# RL7005_IP_SVD register map
Vendor: Realtek
Registers are 32-bit, read-write, reset 0x0 unless marked. A register's access mark holds for its fields unless they carry their own. Offsets are from the block's base; [hi:lo] are bit positions; <NAME> marks a mode.

## PAGE5 (part 2 of 2)
Base 0x40000000
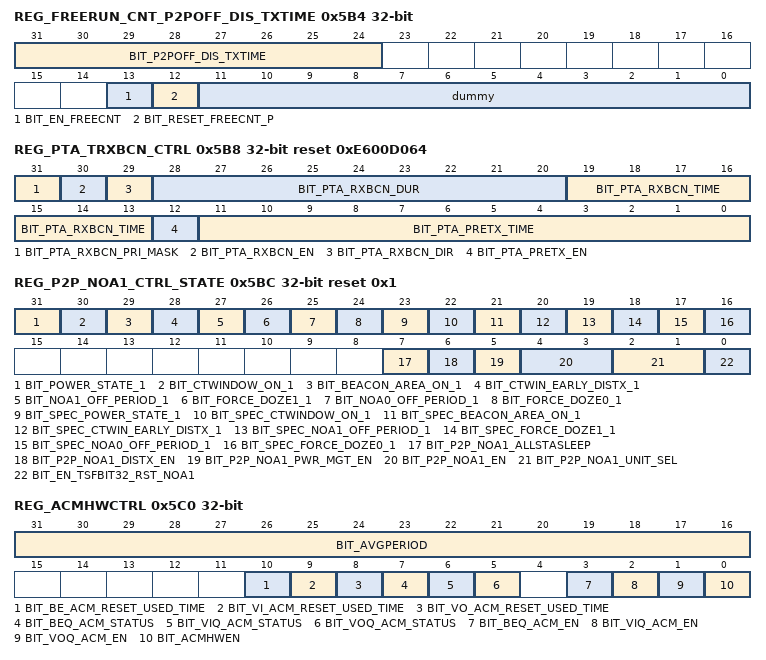
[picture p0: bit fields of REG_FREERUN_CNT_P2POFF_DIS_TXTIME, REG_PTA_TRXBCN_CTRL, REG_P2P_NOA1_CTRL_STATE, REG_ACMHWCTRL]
0x5B4 REG_FREERUN_CNT_P2POFF_DIS_TXTIME access per field
  [31:24] BIT_P2POFF_DIS_TXTIME rw — The time of the disable TX period after the P2P RF off interrupt occur. Unit: 64us.
  [13] BIT_EN_FREECNT rw — enable freerun tsft
  [12] BIT_RESET_FREECNT_P wo — reset pulse of freerun tsft
  [11:0] dummy rw
0x5B8 REG_PTA_TRXBCN_CTRL reset 0xE600D064
  [31] BIT_PTA_RXBCN_PRI_MASK
  [30] BIT_PTA_RXBCN_EN
  [29] BIT_PTA_RXBCN_DIR
  [28:20] BIT_PTA_RXBCN_DUR
  [19:13] BIT_PTA_RXBCN_TIME
  [12] BIT_PTA_PRETX_EN
  [11:0] BIT_PTA_PRETX_TIME — WIFI TX shall wait settle time when antenna is switched from BT to WIFI, if the BT use the same RFAFE as WIFI. Unit: 1us
0x5BC REG_P2P_NOA1_CTRL_STATE access per field reset 0x1
  [31] BIT_POWER_STATE_1 ro — 1: On, 0: Off. (It is including early time. )
  [30] BIT_CTWINDOW_ON_1 ro — Spec time and Beacon Early Time to TBTT Time. (It is including early time. )
  [29] BIT_BEACON_AREA_ON_1 ro — The time is from HOLD Time to BeaconTx or Timeout. (It is including early time. )
  [28] BIT_CTWIN_EARLY_DISTX_1 ro — ctwin_early_distx. (It is including early time. )
  [27] BIT_NOA1_OFF_PERIOD_1 ro — Spec time but exclude BCNDMATIM time for wake. (It is including early time. )
  [26] BIT_FORCE_DOZE1_1 ro — If NoA_Count == 1, this value is 1. else 0. (It is including early time. )
  [25] BIT_NOA0_OFF_PERIOD_1 ro — Spec time but exclude BCNDMATIM time for wake. (It is including early time. )
  [24] BIT_FORCE_DOZE0_1 ro — If NoA_Count == 1, this value is 1. else 0. (It is including early time. )
  [23] BIT_SPEC_POWER_STATE_1 ro — 1: On, 0: Off
  [22] BIT_SPEC_CTWINDOW_ON_1 ro — The time from TBTT <-> CTWEND (with BCNDMATIM early time)
  [21] BIT_SPEC_BEACON_AREA_ON_1 ro — The time is from TBTT to BeaconTx or Timeout
  [20] BIT_SPEC_CTWIN_EARLY_DISTX_1 ro — ctwin_early_distx
  [19] BIT_SPEC_NOA1_OFF_PERIOD_1 ro — Spec time
  [18] BIT_SPEC_FORCE_DOZE1_1 ro — If NoA_Count == 1, this value is 1. else 0.
  [17] BIT_SPEC_NOA0_OFF_PERIOD_1 ro — Spec time
  [16] BIT_SPEC_FORCE_DOZE0_1 ro — If NoA_Count == 1, this value is 1. else 0.
  [7] BIT_P2P_NOA1_ALLSTASLEEP rw — It indicates that the state from CTWindow End to BcnEarly 1: Sleep 0: Wake
  [6] BIT_P2P_NOA1_DISTX_EN rw — 1: Hw will disable TX in P2P_off period 0: Do Nothing
  [5] BIT_P2P_NOA1_PWR_MGT_EN rw — A main switch for P2P PowerSaving 1: Enable 0: Disable
  [4:3] BIT_P2P_NOA1_EN rw — The condition that noa_unit0, [1]-NOA1, [0]-NOA0 1: Enable 0: Disable
  [2:1] BIT_P2P_NOA1_UNIT_SEL rw — The selector for the source of noa unit0. 0 for port 0, 1 for port 1
  [0] BIT_EN_TSFBIT32_RST_NOA1 rw
0x5C0 REG_ACMHWCTRL access per field
  [31:16] BIT_AVGPERIOD rw — In unit of 32 us. It is the value Dot11EDCAAveragingPeriod in SPEC. HW will recalculate used_time every this period. Max is 2 sec
  [10] BIT_BE_ACM_RESET_USED_TIME wo — When HwEn is enabled, software set this bit to inform hardware to reset used_time to 0. Read this bit is always 0.
  [9] BIT_VI_ACM_RESET_USED_TIME wo — When HwEn is enabled, software set this bit to inform hardware to reset used_time to 0. Read this bit is always 0.
  [8] BIT_VO_ACM_RESET_USED_TIME wo — When HwEn is enabled, software set this bit to inform hardware to reset used_time to 0. Read this bit is always 0.
  [7] BIT_BEQ_ACM_STATUS ro — This bit indicates if the used_time >= admitted_time of AC BE when HW ACM. 0: BEQ ACM Not Exceed. 1: BEQ ACM Exceed. Default: 0h
  [6] BIT_VIQ_ACM_STATUS ro — This bit indicates if the used_time >= admitted_time of AC VI when HW ACM. 0: VIQ ACM Not Exceed. 1: VIQ ACM Exceed. Default: 0h
  [5] BIT_VOQ_ACM_STATUS ro — This bit indicates if the used_time >= admitted_time of AC VO when HW ACM. 0: VOQ ACM Not Exceed. 1: VOQ ACM Exceed. Default: 0h
  [3] BIT_BEQ_ACM_EN rw — Set this bit to enable ACM of BE queue. 1: Enable 0: Disable Default: 0h
  [2] BIT_VIQ_ACM_EN rw — Set this bit to enable ACM of VI queue. 1: Enable 0: Disable Default: 0h.
  [1] BIT_VOQ_ACM_EN rw — Set this bit to enable ACM of VO queue. 1: Enable 0: Disable Default: 0h.
  [0] BIT_ACMHWEN rw — Set this bit to enable hardware to take control of ACM. 1: Hardware Control 0: Software Control Default: 0h.
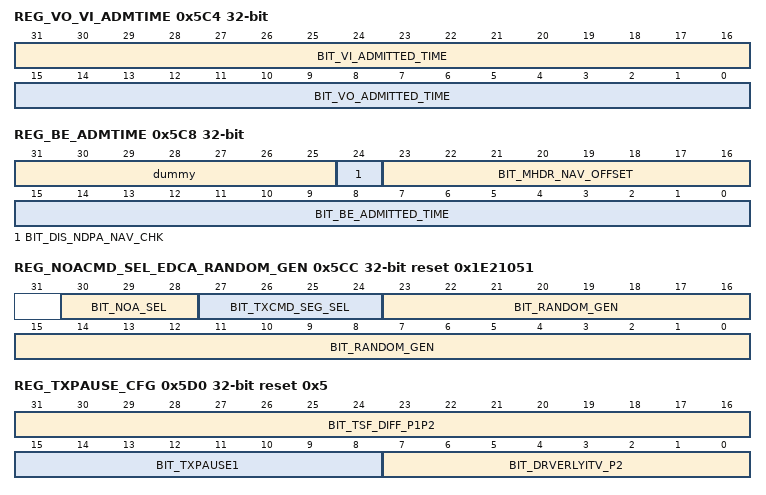
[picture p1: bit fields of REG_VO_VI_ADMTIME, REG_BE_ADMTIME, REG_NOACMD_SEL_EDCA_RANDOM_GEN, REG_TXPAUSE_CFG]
0x5C4 REG_VO_VI_ADMTIME
  [31:16] BIT_VI_ADMITTED_TIME — Admitted_time of VI queue. In unit of 32 microsecond. Calculated and set by driver.
  [15:0] BIT_VO_ADMITTED_TIME — Admitted_time of VO queue. In unit of 32 microsecond. Calculated and set by driver.
0x5C8 REG_BE_ADMTIME
  [31:25] dummy
  [24] BIT_DIS_NDPA_NAV_CHK — 1-->tx NDPA/NDP can cross TBTT,0-->tx NDPA/NDP can't cross TBTT
  [23:16] BIT_MHDR_NAV_OFFSET — NDPA NAV compensation value
  [15:0] BIT_BE_ADMITTED_TIME — Admitted_time of BE queue. In unit of 32 microsecond. Calculated and set by driver.
0x5CC REG_NOACMD_SEL_EDCA_RANDOM_GEN reset 0x1E21051
  [30:28] BIT_NOA_SEL — TX NoA parameter select (noa_unit0~2,parameter0~5) 0: NoA0 , 1:NoA1, 2:NoA2, 3:NoA3, 4:NoA4, default: NoA5 To control the register setting for which NOA. (register 0x05E0[103:0])
  [27:24] BIT_TXCMD_SEG_SEL — [HW Debug Info]To select which one TXCMD Segment. For example, 可以在0x5CF[3:0]填 0 or 6 讀取 0x5F8[7:0] : Tx Agg 0x5F9[7:0] : Tx Rate
  [23:0] BIT_RANDOM_GEN — Random number generator polynomial
0x5D0 REG_TXPAUSE_CFG access per field reset 0x5
  [31:16] BIT_TSF_DIFF_P1P2 ro — the difference of beacon count down value between port0 and port1, unit is TU
  [15:8] BIT_TXPAUSE1 rw — same as 0x522[7:0], allow FW/DR to control pause jointly
  [7:0] BIT_DRVERLYITV_P2 rw — Time to send interrupt to notify driver to change beacon content. Time unit is TU. It is used to wake up early at DriverEarlyTime. For port 2
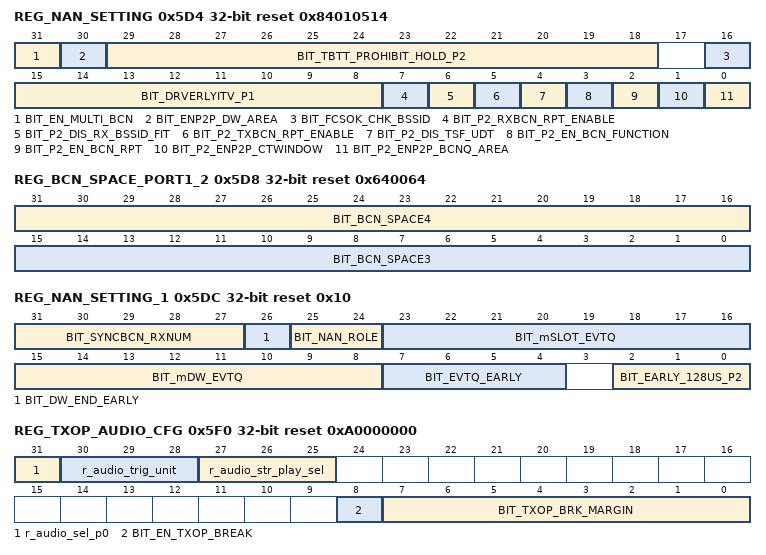
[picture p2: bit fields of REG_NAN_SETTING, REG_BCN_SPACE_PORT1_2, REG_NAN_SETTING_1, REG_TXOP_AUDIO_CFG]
0x5D4 REG_NAN_SETTING reset 0x84010514
  [31] BIT_EN_MULTI_BCN — enable multiple beacons of port0~port2
  [30] BIT_ENP2P_DW_AREA — DW condition for P2P,for port2
  [29:18] BIT_TBTT_PROHIBIT_HOLD_P2 — the predicted hold time after tbtt for beacon tx of port2, unit is 32us
  [16] BIT_FCSOK_CHK_BSSID — 1:HW will check bssid when fcsok
  [15:8] BIT_DRVERLYITV_P1 — Time to send interrupt to notify driver to change beacon content. Time unit is TU. It is used to wake up early at DriverEarlyTime. For port1
  [7] BIT_P2_RXBCN_RPT_ENABLE — When this bit asserted, RXBCNOK report is issued
  [6] BIT_P2_DIS_RX_BSSID_FIT — 0:HW will handle rx_beacon 1:HW will ignore rx_beacon_pk
  [5] BIT_P2_TXBCN_RPT_ENABLE — When this bit asserted, then TXBCN ERROR report is issued
  [4] BIT_P2_DIS_TSF_UDT — When set, disable clint 2 TSF update when beacon frames or probe response frames are received.
  [3] BIT_P2_EN_BCN_FUNCTION — When this bit is set, TSF and other beacon related functions are then enabled.
  [2] BIT_P2_EN_BCN_RPT — When this bit asserted, txbcnok_int and txbcnerr_int will valid.
  [1] BIT_P2_ENP2P_CTWINDOW — 1: Enable P2P CTN WINDOWS function. 0: Disable P2P CTN WINDOWS function.
  [0] BIT_P2_ENP2P_BCNQ_AREA — 1: Enable P2P BCN area on function. 0 : Disable P2P BCN area on function.
0x5D8 REG_BCN_SPACE_PORT1_2 reset 0x640064
  [31:16] BIT_BCN_SPACE4 — Unit is ms. the beacon space of port2 disc beacon. default is 100ms
  [15:0] BIT_BCN_SPACE3 — sync beacon space of port1
0x5DC REG_NAN_SETTING_1 reset 0x10
  [31:27] BIT_SYNCBCN_RXNUM — if DW is permitted to end early, the number of rx sync beacons is defined in this register
  [26] BIT_DW_END_EARLY — when set, the DW window end earlier than spec definition. When sync bcn and SDF had tx, and rx enough sync bcns defined by 0x5DC[31:27]. DW can early end
  [25:24] BIT_NAN_ROLE — the role of NAN device, including master, no-master sync, and no-master no-sync.
  [23:16] BIT_mSLOT_EVTQ — evtq packet will tx in the m-th SLOT of the m-th DWs
  [15:8] BIT_mDW_EVTQ — evtq packet will tx in the m-th SLOT of the m-th DWs
  [7:4] BIT_EVTQ_EARLY — the early time of evtq tx window. unit is TU
  [2:0] BIT_EARLY_128US_P2 — the BCN EARLY interrupt find tune with unit 128us. The Total Early time of BCN early interrupt is the ERLYINTIM x 1ms + EARLY_128us x 128us.
0x5E0 REG_NOA_PARAM_V1 reset 0x1000
  [31:0] BIT_NOA_DURATION_V1 — The maximum duration in units of microseconds that the P2P Group Owner shall remain absent following the start of a Notice of Absence interval.
0x5E4 REG_NOA_PARAM_V2 reset 0x3000
  [31:0] BIT_NOA_INTERVAL_V2 — The length of the Notice of Absence interval in units of microseconds.
0x5E8 REG_NOA_PARAM_V3 reset 0x1000
  [31:0] BIT_NOA_START_TIME_V3 — The start time for the schedule expressed in terms of the lower 4 bytes of the TSF timer.
0x5EC REG_NOA_PARAM_4 reset 0x3
  [7:0] BIT_NOA_COUNT_V4 — indicates the number of absence intervals
0x5F0 REG_TXOP_AUDIO_CFG reset 0xA0000000
  [31] r_audio_sel_p0 — 1: select P0's TSFT to trigger audio latch count
  [30:28] r_audio_trig_unit — 0: trigger audio latch period is 1ms 1: period is 2ms 2: period is 4ms 3: period is 8ms ...... 6: period is 64ms 7: period is 128ms
  [27:25] r_audio_str_play_sel — select ps_timer interrput for audio start play function 1: select ps_timer_a int 2: select ps_timer_b int 3: select ps_timer_c int 4: select ps_timer_d int 5: select ps_timer_e int else: TIE0
  [8] BIT_EN_TXOP_BREAK — 1: enable TXOP break gen_cmd and TXOP abort TX
  [7:0] BIT_TXOP_BRK_MARGIN — extra transtime during TXOP, unit: 2us if data_transtime + BIT_TXOP_BRK_MARGIN*2 exceed the remaining TXOP count, will abort this TX
0x5F4 REG_SCHEDULER_DBG ro
  [31:0] BIT_DBG_SCHEDULER
0x5F8 REG_SCH_TXCMD ro
  [31:0] BIT_SCH_TXCMD — Scheduler TXCMD Content
0x5FC REG_PAGE5_DUMMY reset 0xFFFF0000
  [31:0] BIT_DUMMY — Dummy
0x1500 REG_PS_TIMER_A_L
  [31:0] BIT_PS_TIMER_A_L — When the TSF (that select by reg 0x1520 [25:24]) matches the content of this register, the PS_TIMER_A_INT interrupt is issued
0x1504 REG_PS_TIMER_A_H
  [31:0] BIT_PS_TIMER_A_H — When the TSF (that select by reg 0x1520 [25:24]) matches the content of this register, the PS_TIMER_A_INT interrupt is issued
0x1508 REG_PS_TIMER_B_L
  [31:0] BIT_PS_TIMER_B_L — When the TSF (that select by reg 0x1520 [29:28]) matches the content of this register, the PS_TIMER_B_INT interrupt is issued
0x150C REG_PS_TIMER_B_H
  [31:0] BIT_PS_TIMER_B_H — When the TSF(that select by reg 0x1520 [29:28]) matches the content of this register, the PS_TIMER_B_INT interrupt is issued
0x1510 REG_PS_TIMER_C_L
  [31:0] BIT_PS_TIMER_C_L — When the TSF(that select by reg 0x1520 [21:20]) matches the content of this register, the PS_TIMER_C_INT interrupt is issued
0x1514 REG_PS_TIMER_C_H
  [31:0] BIT_PS_TIMER_C_H — When the TSF(that select by reg 0x1520 [21:20]) matches the content of this register, the PS_TIMER_C_INT interrupt is issued
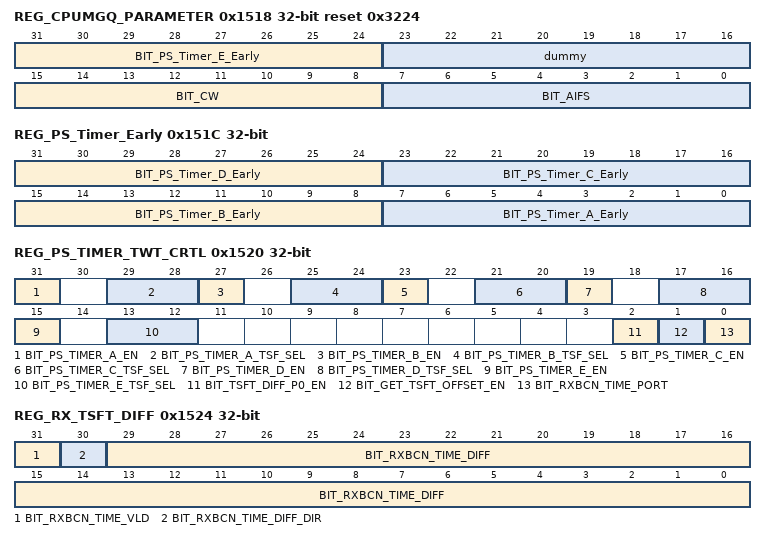
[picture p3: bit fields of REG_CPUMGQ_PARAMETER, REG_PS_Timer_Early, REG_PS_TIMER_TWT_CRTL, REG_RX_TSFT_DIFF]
0x1518 REG_CPUMGQ_PARAMETER reset 0x3224
  [31:24] BIT_PS_Timer_E_Early — It is used to wake up early at PS_Timer_E_Early Time. Time unit is 32us.
  [23:16] dummy
  [15:8] BIT_CW — ECWmin and ECWmax encode the values of Cwmin and Cwmax respectively in an exponent form. Ex: Cwmax = 2^(ECWmax)-1 Default: BK = Ah/5h; BE = Ah/5h; VI = 5h/4h; VO = 4h/3h.
  [7:0] BIT_AIFS — Arbitrary Inter frame space In unit of microsecond. AIFS indicates the time a non-AP QSTA should defer before either invoking a backoff or starting a transmission Default: BK = 49h; BE = 25h; VI = 1Ch; VO = 1Ch
0x151C REG_PS_Timer_Early
  [31:24] BIT_PS_Timer_D_Early — It is used to wake up early at PS_Timer_D_Early Time. Time unit is 32us.
  [23:16] BIT_PS_Timer_C_Early — It is used to wake up early at PS_Timer_C_Early Time. Time unit is 32us.
  [15:8] BIT_PS_Timer_B_Early — It is used to wake up early at PS_Timer_B_Early Time. Time unit is 32us.
  [7:0] BIT_PS_Timer_A_Early — It is used to wake up early at PS_Timer_A_Early Time. Time unit is 32us.
0x1520 REG_PS_TIMER_TWT_CRTL
  [31] BIT_PS_TIMER_A_EN — Enable PS_TIMER_B
  [29:28] BIT_PS_TIMER_A_TSF_SEL — 0 for port 0, 1 for port1, 2 for port2, 3 for freerun
  [27] BIT_PS_TIMER_B_EN — Enable PS_TIMER_A
  [25:24] BIT_PS_TIMER_B_TSF_SEL — 0 for port 0, 1 for port1, 2 for port2, 3 for freerun
  [23] BIT_PS_TIMER_C_EN — Enable PS_TIMER_C
  [21:20] BIT_PS_TIMER_C_TSF_SEL — 0 for port 0, 1 for port1, 2 for port2, 3 for freerun
  [19] BIT_PS_TIMER_D_EN — Enable PS_TIMER_D
  [17:16] BIT_PS_TIMER_D_TSF_SEL — 0 for port 0, 1 for port1, 2 for port2, 3 for freerun
  [15] BIT_PS_TIMER_E_EN — Enable PS_TIMER_E
  [13:12] BIT_PS_TIMER_E_TSF_SEL — 0 for port 0, 1 for port1, 2 for port2, 3 for freerun
  [2] BIT_TSFT_DIFF_P0_EN
  [1] BIT_GET_TSFT_OFFSET_EN — 1: Enable Enable get TSFT offset function
  [0] BIT_RXBCN_TIME_PORT — select port for report the TSFT 0: port0 1: port1 default is port0.
0x1524 REG_RX_TSFT_DIFF ro
  [31] BIT_RXBCN_TIME_VLD — 1: indicate [30:0] is valid. Write 1 to clear this bit
  [30] BIT_RXBCN_TIME_DIFF_DIR — 1: wmac_rx_tsf > TSFT 0: wmac_rx_tsf <= TSFT
  [29:0] BIT_RXBCN_TIME_DIFF — unit:1us wmac_rx_tsf - TSFT (selected by 0x1520[0]). [30] is the sign bit
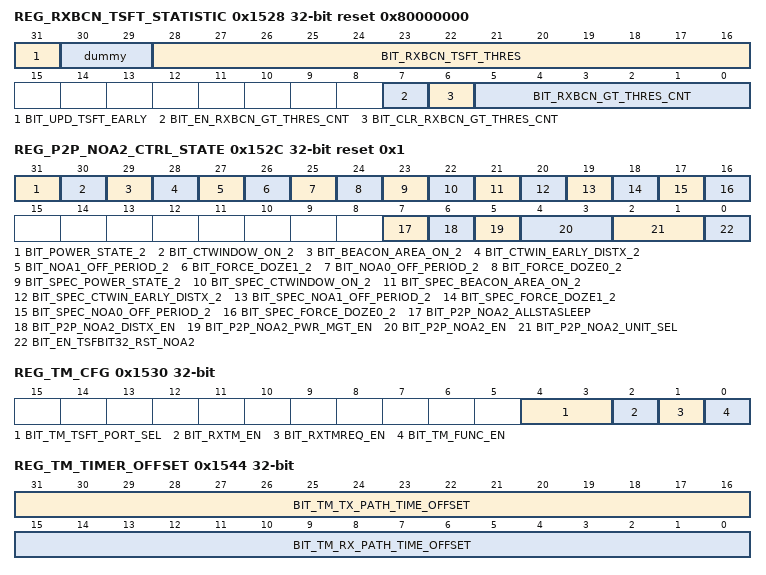
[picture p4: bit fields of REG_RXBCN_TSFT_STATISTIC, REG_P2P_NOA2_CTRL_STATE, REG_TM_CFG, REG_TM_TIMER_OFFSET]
0x1528 REG_RXBCN_TSFT_STATISTIC access per field reset 0x80000000
  [31] BIT_UPD_TSFT_EARLY rw — 0: don't update TSFT when the following scenarios occur: tim_no_hit, |TSFT - rxbcn.timestamp| <= BIT_RXBCN_TSFT_THRES, and r_wait_rxbcn_finish = 1 1: update TSFT
  [30:29] dummy rw
  [28:16] BIT_RXBCN_TSFT_THRES rw — used for LPS MAC, if |TSFT - rxbcn.timestamp| > BIT_RXBCN_TSFT_THRES, need to wait fcsok. Else, update TSFT at wmac_rxtsf_rdy (before fcsok) unit is 1us,max is 8ms
  [7] BIT_EN_RXBCN_GT_THRES_CNT rw — enable the counter of BIT_RXBCN_GT_THRES_CNT
  [6] BIT_CLR_RXBCN_GT_THRES_CNT wo — clear the BIT_RXBCN_GT_THRES_CNT to 0
  [5:0] BIT_RXBCN_GT_THRES_CNT ro — valid when BIT_EN_RXBCN_GT_THRES_CNT = 1. counter the number of beacon with the |TSFT - rxbcn.timestamp| exceed the threshold
0x152C REG_P2P_NOA2_CTRL_STATE access per field reset 0x1
  [31] BIT_POWER_STATE_2 ro — 1: On, 0: Off. (It is including early time. )
  [30] BIT_CTWINDOW_ON_2 ro — Spec time and Beacon Early Time to TBTT Time. (It is including early time. )
  [29] BIT_BEACON_AREA_ON_2 ro — The time is from HOLD Time to BeaconTx or Timeout. (It is including early time. )
  [28] BIT_CTWIN_EARLY_DISTX_2 ro — ctwin_early_distx. (It is including early time. )
  [27] BIT_NOA1_OFF_PERIOD_2 ro — Spec time but exclude BCNDMATIM time for wake. (It is including early time. )
  [26] BIT_FORCE_DOZE1_2 ro — If NoA_Count == 1, this value is 1. else 0. (It is including early time. )
  [25] BIT_NOA0_OFF_PERIOD_2 ro — Spec time but exclude BCNDMATIM time for wake. (It is including early time. )
  [24] BIT_FORCE_DOZE0_2 ro — If NoA_Count == 1, this value is 1. else 0. (It is including early time. )
  [23] BIT_SPEC_POWER_STATE_2 ro — 1: On, 0: Off
  [22] BIT_SPEC_CTWINDOW_ON_2 ro — The time from TBTT <-> CTWEND (with BCNDMATIM early time)
  [21] BIT_SPEC_BEACON_AREA_ON_2 ro — The time is from TBTT to BeaconTx or Timeout
  [20] BIT_SPEC_CTWIN_EARLY_DISTX_2 ro — ctwin_early_distx
  [19] BIT_SPEC_NOA1_OFF_PERIOD_2 ro — Spec time
  [18] BIT_SPEC_FORCE_DOZE1_2 ro — If NoA_Count == 1, this value is 1. else 0.
  [17] BIT_SPEC_NOA0_OFF_PERIOD_2 ro — Spec time
  [16] BIT_SPEC_FORCE_DOZE0_2 ro — If NoA_Count == 1, this value is 1. else 0.
  [7] BIT_P2P_NOA2_ALLSTASLEEP rw — It indicates that the state from CTWindow End to BcnEarly 1: Sleep 0: Wake
  [6] BIT_P2P_NOA2_DISTX_EN rw — 1: Hw will disable TX in P2P_off period 0: Do Nothing
  [5] BIT_P2P_NOA2_PWR_MGT_EN rw — A main switch for P2P PowerSaving 1: Enable 0: Disable
  [4:3] BIT_P2P_NOA2_EN rw — The condition that noa_unit0, [1]-NOA1, [0]-NOA0 1: Enable 0: Disable
  [2:1] BIT_P2P_NOA2_UNIT_SEL rw — The selector for the source of noa unit0. 0 for port 0, 1 for port 1, 2 for port 2
  [0] BIT_EN_TSFBIT32_RST_NOA2 rw
0x1530 REG_TM_CFG
  [4:3] BIT_TM_TSFT_PORT_SEL — selected TM timer port 0: port0; 1: port1; 2: port2; 3: freerun
  [2] BIT_RXTM_EN — 1: HW will parsing rx packet, to find TM frame
  [1] BIT_RXTMREQ_EN — 1: HW will parsing rx packet, to find TM request frame
  [0] BIT_TM_FUNC_EN — 1: Enable Timing Measurement function
0x1534 REG_TM_TSFT_T1 ro
  [31:0] BIT_TM_TSFT_T1 — Latch tsft timer of Tx TM frame, unit: 1us
0x1538 REG_TM_TSFT_T2 ro
  [31:0] BIT_TM_TSFT_T2 — Latch tsft timer of Rx TM frame, unit: 1us
0x153C REG_TM_TSFT_T3 ro
  [31:0] BIT_TM_TSFT_T3 — Latch tsft timer of Tx ACK frame, unit: 1us
0x1540 REG_TM_TSFT_T4 ro
  [31:0] BIT_TM_TSFT_T4 — Latch tsft timer of Rx ACK frame, unit: 1us
0x1544 REG_TM_TIMER_OFFSET
  [31:16] BIT_TM_TX_PATH_TIME_OFFSET — Compensate the time, from PHYTXON rising edge to transmit antenna connector. unit: 1us
  [15:0] BIT_TM_RX_PATH_TIME_OFFSET — Compensate the time, from receive antenna connector to DATAON rising edge. unit: 1us
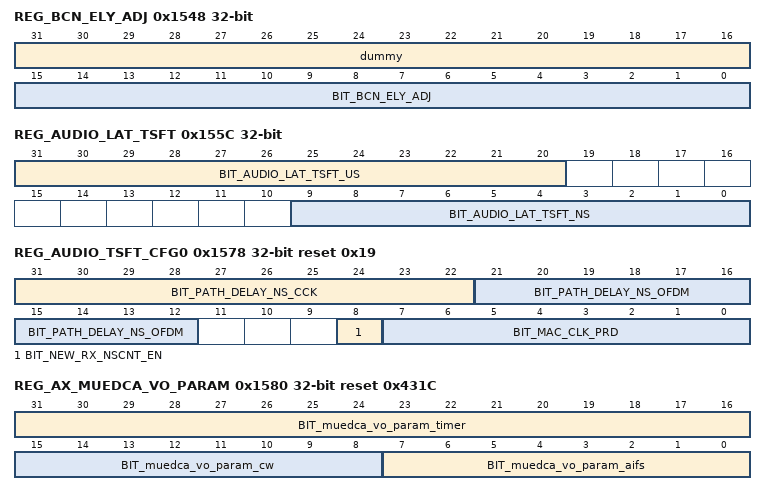
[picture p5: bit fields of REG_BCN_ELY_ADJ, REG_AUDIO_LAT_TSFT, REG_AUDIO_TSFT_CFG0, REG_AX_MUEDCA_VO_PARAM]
0x1548 REG_BCN_ELY_ADJ
  [31:16] dummy
  [15:0] BIT_BCN_ELY_ADJ — beacon early time adjust, unit is 32us
0x154C REG_PS_TIMER_D_L
  [31:0] BIT_PS_TIMER_D_L — When the TSF(that select by reg 0x1520 [16:17]) matches the content of this register, the PS_TIMER_D_INT interrupt is issued
0x1550 REG_PS_TIMER_D_H
  [31:0] BIT_PS_TIMER_D_H — When the TSF(that select by reg 0x1520 [16:17]) matches the content of this register, the PS_TIMER_D_INT interrupt is issued
0x1554 REG_PS_TIMER_E_L
  [31:0] BIT_PS_TIMER_E_L — When the TSF (that select by reg 0x1520 [13:12]) matches the content of this register, the PS_TIMER_E_INT interrupt is issued
0x1558 REG_PS_TIMER_E_H
  [31:0] BIT_PS_TIMER_E_H — When the TSF (that select by reg 0x1520 [13:12]) matches the content of this register, the PS_TIMER_E_INT interrupt is issued
0x155C REG_AUDIO_LAT_TSFT ro
  [31:20] BIT_AUDIO_LAT_TSFT_US — low 22bits of audio latch tsft_us
  [9:0] BIT_AUDIO_LAT_TSFT_NS — audio latch tsft_ns
0x1578 REG_AUDIO_TSFT_CFG0 reset 0x19
  [31:22] BIT_PATH_DELAY_NS_CCK — the NS part of RX CCK1M PATH DELAY
  [21:12] BIT_PATH_DELAY_NS_OFDM — the NS part of RX OFDM6M PATH DELAY
  [8] BIT_NEW_RX_NSCNT_EN — 1: enable the new ns counter of rx 0: follow old ns counter as tx
  [7:0] BIT_MAC_CLK_PRD — set the period of MAC CLK, default 40M-25ns
0x1580 REG_AX_MUEDCA_VO_PARAM reset 0x431C
  [31:16] BIT_muedca_vo_param_timer — MU EDCA TIMER, in units of 32 us Note: SPEC: The MU EDCA Timer field (8b) indicates the duration of time, in units of 8 TUs
  [15:8] BIT_muedca_vo_param_cw — ECWmin and ECWmax encode the values of Cwmin and Cwmax respectively in an exponent form. Ex: Cwmax = 2^(ECWmax)-1 Default: BK = Ah/5h; BE = Ah/5h; VI = 5h/4h; VO = 4h/3h.
  [7:0] BIT_muedca_vo_param_aifs — Arbitrary Inter frame space In unit of microsecond. AIFS indicates the time a non-AP QSTA should defer before either invoking a backoff or starting a transmission Default: BK = 49h; BE = 25h; VI = 1Ch; VO = 1Ch.
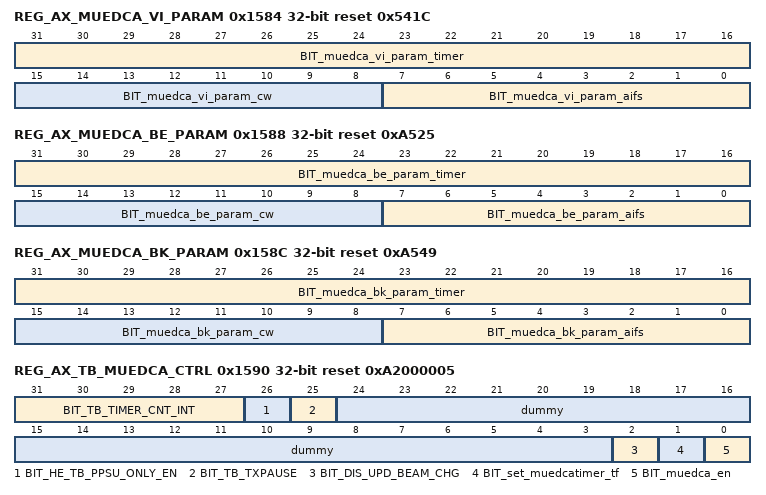
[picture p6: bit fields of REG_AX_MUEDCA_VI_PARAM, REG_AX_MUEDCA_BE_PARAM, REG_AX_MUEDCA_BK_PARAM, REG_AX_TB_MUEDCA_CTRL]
0x1584 REG_AX_MUEDCA_VI_PARAM reset 0x541C
  [31:16] BIT_muedca_vi_param_timer — MU EDCA TIMER, in units of 32 us Note: SPEC: The MU EDCA Timer field (8b) indicates the duration of time, in units of 8 TUs
  [15:8] BIT_muedca_vi_param_cw — ECWmin and ECWmax encode the values of Cwmin and Cwmax respectively in an exponent form. Ex: Cwmax = 2^(ECWmax)-1 Default: BK = Ah/5h; BE = Ah/5h; VI = 5h/4h; VO = 4h/3h.
  [7:0] BIT_muedca_vi_param_aifs — Arbitrary Inter frame space In unit of microsecond. AIFS indicates the time a non-AP QSTA should defer before either invoking a backoff or starting a transmission Default: BK = 49h; BE = 25h; VI = 1Ch; VO = 1Ch.
0x1588 REG_AX_MUEDCA_BE_PARAM reset 0xA525
  [31:16] BIT_muedca_be_param_timer — MU EDCA TIMER, in units of 32 us Note: SPEC: The MU EDCA Timer field (8b) indicates the duration of time, in units of 8 TUs
  [15:8] BIT_muedca_be_param_cw — ECWmin and ECWmax encode the values of Cwmin and Cwmax respectively in an exponent form. Ex: Cwmax = 2^(ECWmax)-1 Default: BK = Ah/5h; BE = Ah/5h; VI = 5h/4h; VO = 4h/3h.
  [7:0] BIT_muedca_be_param_aifs — Arbitrary Inter frame space In unit of microsecond. AIFS indicates the time a non-AP QSTA should defer before either invoking a backoff or starting a transmission Default: BK = 49h; BE = 25h; VI = 1Ch; VO = 1Ch.
0x158C REG_AX_MUEDCA_BK_PARAM reset 0xA549
  [31:16] BIT_muedca_bk_param_timer — MU EDCA TIMER, in units of 32 us Note: SPEC: The MU EDCA Timer field (8b) indicates the duration of time, in units of 8 TUs
  [15:8] BIT_muedca_bk_param_cw — ECWmin and ECWmax encode the values of Cwmin and Cwmax respectively in an exponent form. Ex: Cwmax = 2^(ECWmax)-1 Default: BK = Ah/5h; BE = Ah/5h; VI = 5h/4h; VO = 4h/3h.
  [7:0] BIT_muedca_bk_param_aifs — Arbitrary Inter frame space In unit of microsecond. AIFS indicates the time a non-AP QSTA should defer before either invoking a backoff or starting a transmission Default: BK = 49h; BE = 25h; VI = 1Ch; VO = 1Ch.
0x1590 REG_AX_TB_MUEDCA_CTRL reset 0xA2000005
  [31:27] BIT_TB_TIMER_CNT_INT — the initial value of th_timer, unit: us
  [26] BIT_HE_TB_PPSU_ONLY_EN — asserted if the TWT is trigger-enabled TWT
  [25] BIT_TB_TXPAUSE — valid if BIT_HE_TB_PPSU_ONLY_EN = 1; select pause edca or not during TWT-SP; default is 1, pause. A TWT requesting STA should not transmit frames to the TWT responding STA outside of negotiated TWT SPs and should not transmit frames that are not contained within HE TB PPDUs to the TWT responding STA within trigger-enabled TWT SPs
  [24:3] dummy
  [2] BIT_DIS_UPD_BEAM_CHG — 1: txcmd_beam_change TIE 0 0: first PPDU in TXOP will assert txcmd_beam_change
  [1] BIT_set_muedcatimer_tf — 1: enable HW updating MUEDCATimer after Tx HE TB PPDU 0: disable HW updating MUEDCATimer after Tx HE TB PPDU
  [0] BIT_muedca_en — 1: enable HW updating MUEDCATimer 0: disable HW updating MUEDCATimer
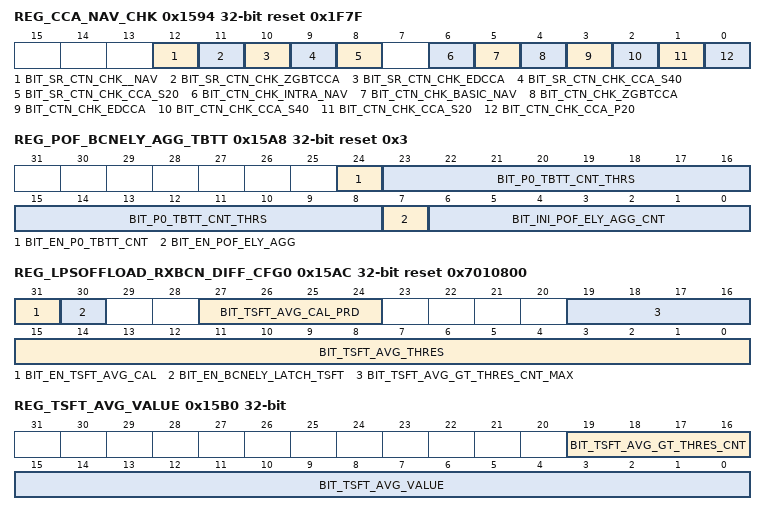
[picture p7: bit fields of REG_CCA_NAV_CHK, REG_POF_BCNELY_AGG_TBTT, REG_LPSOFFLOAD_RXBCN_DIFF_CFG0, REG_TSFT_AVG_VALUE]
0x1594 REG_CCA_NAV_CHK reset 0x1F7F
  [12] BIT_SR_CTN_CHK__NAV — When BASIC or INTRA NAV > 0 in the AIFS/Backoff before active TX 0: Can backoff, can TX 1: Cannot backoff, cannot TX
  [11] BIT_SR_CTN_CHK_ZGBTCCA — When ~GNT_WL(BT/ZigBee) assert in the AIFS/Backoff before active TX 0: Can backoff, can TX 1: Cannot backoff, cannot TX
  [10] BIT_SR_CTN_CHK_EDCCA — When EDCCA assert in the AIFS/Backoff before active TX 0: Can backoff, can TX 1: Cannot backoff, cannot TX
  [9] BIT_SR_CTN_CHK_CCA_S40 — When SECONDARY_CCA_40 assert in the AIFS/Backoff before active TX 0: Can backoff, can TX 1: Can backoff, cannot TX
  [8] BIT_SR_CTN_CHK_CCA_S20 — When SECONDARY_CCA_20 assert in the AIFS/Backoff before active TX 0: Can backoff, can TX 1: Can backoff, cannot TX
  [6] BIT_CTN_CHK_INTRA_NAV — When INTRA NAV > 0 in the AIFS/Backoff before active TX 0: Can backoff, can TX 1: Cannot backoff, cannot TX
  [5] BIT_CTN_CHK_BASIC_NAV — When BASIC NAV > 0 in the AIFS/Backoff before active TX 0: Can backoff, can TX 1: Cannot backoff, cannot TX
  [4] BIT_CTN_CHK_ZGBTCCA — When ~GNT_WL(BT/ZigBee) assert in the AIFS/Backoff before active TX 0: Can backoff, can TX 1: Cannot backoff, cannot TX
  [3] BIT_CTN_CHK_EDCCA — When EDCCA assert in the AIFS/Backoff before active TX 0: Can backoff, can TX 1: Cannot backoff, cannot TX
  [2] BIT_CTN_CHK_CCA_S40 — When SECONDARY_CCA_40 assert in the AIFS/Backoff before active TX 0: Can backoff, can TX 1: Can backoff, cannot TX
  [1] BIT_CTN_CHK_CCA_S20 — When SECONDARY_CCA_20 assert in the AIFS/Backoff before active TX 0: Can backoff, can TX 1: Can backoff, cannot TX
  [0] BIT_CTN_CHK_CCA_P20 — When CCA assert in the AIFS/Backoff before active TX 0: Can backoff, can TX 1: Cannot backoff, cannot TX
0x1598 REG_TSFT_HIOE_RFON_L ro
  [31:0] BIT_TSFT_AT_HIOE_RFON_L — when hioe_int_chn_on asserted, latch the tsft[31:0] (select port by 0x1520[0])
0x159C REG_TSFT_HIOE_RFON_H ro
  [31:0] BIT_TSFT_AT_HIOE_RFON_H — when hioe_int_chn_on asserted, latch the tsft[63:32] (select port by 0x1520[0])
0x15A0 REG_TSFT_BCN_CCAUP_L ro
  [31:0] BIT_TSFT_AT_BCN_CCA_UP_L — when CCA asserted, latch the tsft[31:0] (select port by 0x1520[0]). updated to this register after judging that it is a beacon frame
0x15A4 REG_TSFT_BCN_CCAUP_H ro
  [31:0] BIT_TSFT_AT_BCN_CCA_UP_H — when CCA asserted, latch the tsft[63:32] (select port by 0x1520[0]). updated to this register after judging that it is a beacon frame
0x15A8 REG_POF_BCNELY_AGG_TBTT reset 0x3
  [24] BIT_EN_P0_TBTT_CNT — enable the tbtt counter function.
  [23:8] BIT_P0_TBTT_CNT_THRS — P0's TBTT counter threshold . Valid when BIT_EN_P0_TBTT_CNT = 1. when tbtt_cnt >= BIT_P0_TBTT_CNT_THRS, assert p0_tbtt_agg_int.
  [7] BIT_EN_POF_ELY_AGG — update bcn_ely_agg initial value of P0 to BIT_INI_POF_ELY_AGG_CNT 1: enable 0: disable
  [6:0] BIT_INI_POF_ELY_AGG_CNT — bcn_ely_agg initial value of P0. Valid when BIT_EN_POF_ELY_AGG = 1
0x15AC REG_LPSOFFLOAD_RXBCN_DIFF_CFG0 reset 0x7010800
  [31] BIT_EN_TSFT_AVG_CAL — 1: calculate the average value of deltaTSFT(latch hioe_int_chn_on and cca_up) in specified period
  [30] BIT_EN_BCNELY_LATCH_TSFT — 1: latch TSFT to BIT_TSFT_AT_HIOE_RFON (0x153C) when P0's bcn_early int asserted
  [27:24] BIT_TSFT_AVG_CAL_PRD — 2^(BIT_TSFT_AVG_CAL_PERIOD), default is 128 times
  [19:16] BIT_TSFT_AVG_GT_THRES_CNT_MAX — The max times of the BIT_TSFT_AVG_VALUE greater than BIT_TSFT_AVG_THRES, if the BIT_TSFT_AVG_VALUE exceeds the BIT_TSFT_AVG_THRES several times in a row, and the number exceeds the BIT_TSFT_AVG_GT_THRES_CNT_MAX, generate an interrupt
  [15:0] BIT_TSFT_AVG_THRES — The threshold of deltaTSFT(latch hioe_int_chn_on and cca_up), unit us
0x15B0 REG_TSFT_AVG_VALUE ro
  [19:16] BIT_TSFT_AVG_GT_THRES_CNT — statistic the times of the BIT_TSFT_AVG_VALUE than BIT_TSFT_AVG_THRES
  [15:0] BIT_TSFT_AVG_VALUE — the average value of deltaTSFT(latch hioe_int_chn_on and cca_up) in specified period
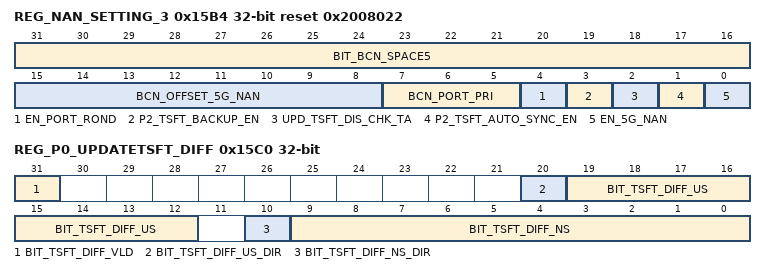
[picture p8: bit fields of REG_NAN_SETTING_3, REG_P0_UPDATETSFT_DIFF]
0x15B4 REG_NAN_SETTING_3 reset 0x2008022
  [31:16] BIT_BCN_SPACE5 — Unit is ms. the beacon space of port2 sync beacon. default is 512ms
  [15:8] BCN_OFFSET_5G_NAN — Unit is ms. the tbtt offset between 2.4G sync beacon and 5G sync bcn. Default is 128ms
  [7:5] BCN_PORT_PRI — the priority of ports 000: no priority 001: port2 sync bcn has higher priority than P0/P1, P2 sync > P0/P1 010: port0 has higher priority than P2 sync bcn, P0 > P2 sync > P1 011: port1 has higher priority than P2 sync bcn, P1 > P2 sync > P0 100: port0 and port1 has higher priority than P2 sync bcn, P0/P1 > P2 sync
  [4] EN_PORT_ROND — 1: enable round-robin of P2 disc beacon and P0/1 beacon
  [3] P2_TSFT_BACKUP_EN — 1:en p2 backup tsft
  [2] UPD_TSFT_DIS_CHK_TA — 1: don't check TA_FIT when update NAN tsft
  [1] P2_TSFT_AUTO_SYNC_EN — 1: enable HW auto tsft sync, when sync beacon frames are received, auto update RX.timestamp + RX path delay to TSFT_P2_0
  [0] EN_5G_NAN — 1: enable 5G NAN mode 0: only 2.4G NAN
0x15B8 REG_P2_BACKUP_TSFTR_L reset 0x1
  [31:0] P2_BACKUP_TSF_TIMER_L — low 32bits of port2's backup tsft (NAN)
0x15BC REG_P2_BACKUP_TSFTR_H
  [31:0] P2_BACKUP_TSF_TIMER_H — high 32bits of port2's backup tsft (NAN)
0x15C0 REG_P0_UPDATETSFT_DIFF ro
  [31] BIT_TSFT_DIFF_VLD — 1: indicate [20:0] is valid. 0: wmac_rx_tsf <= TSFT
  [20] BIT_TSFT_DIFF_US_DIR — 1: update_tsft_us > TSFT_us 0: update_tsft_us <= TSFT_us
  [19:12] BIT_TSFT_DIFF_US — unit:1us update_tsft_us - TSFT. [20] is the sign bit if diff >=255, this value would be 8'hff
  [10] BIT_TSFT_DIFF_NS_DIR — 1: update_tsft_ns > TSFT_ns 0: update_tsft_ns <= TSFT_ns
  [9:0] BIT_TSFT_DIFF_NS — unit:1ns update_tsft_ns - TSFT. [10] is the sign bit
